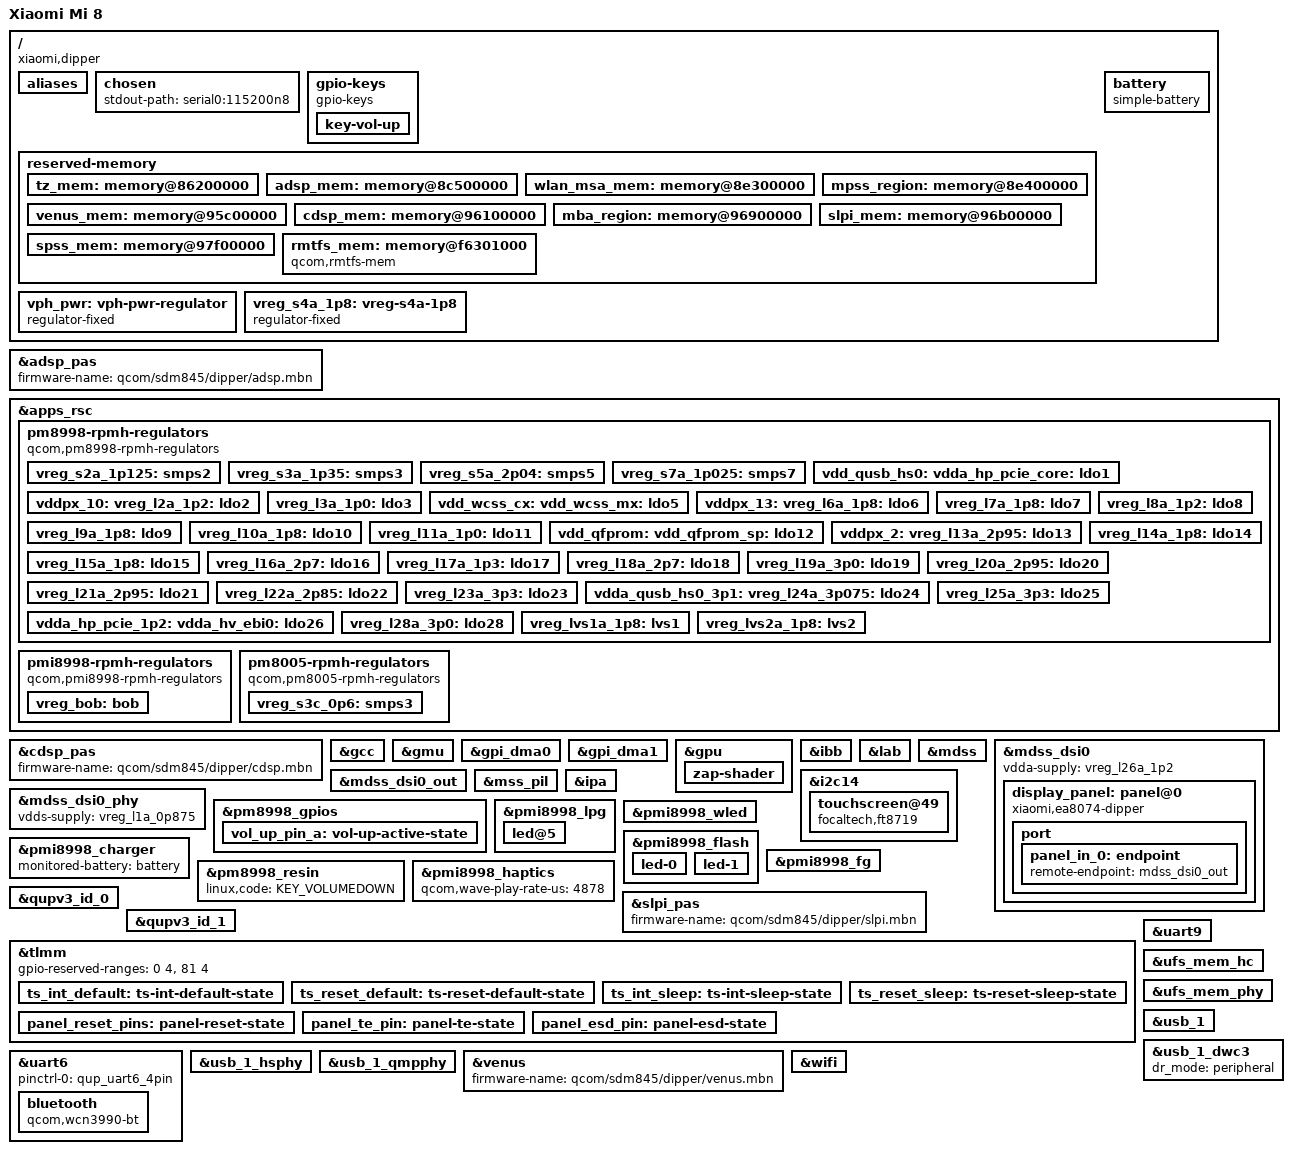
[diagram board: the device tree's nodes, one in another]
// SPDX-License-Identifier: GPL-2.0
/*
 * SDM845 Xiaomi Mi 8 (dipper) device tree source
 *
 * Copyright (c) 2024, Arseniy Velikanov <me@adomerle.xyz>
 */

/dts-v1/;

#include <dt-bindings/leds/common.h>
#include <dt-bindings/pinctrl/qcom,pmic-gpio.h>
#include <dt-bindings/regulator/qcom,rpmh-regulator.h>
#include "sdm845.dtsi"
#include "pm8998.dtsi"
#include "pmi8998.dtsi"

/*
 * Delete following upstream (sdm845.dtsi) reserved
 * memory mappings which are different in this device.
 */
/delete-node/ &tz_mem;
/delete-node/ &adsp_mem;
/delete-node/ &wlan_msa_mem;
/delete-node/ &mpss_region;
/delete-node/ &venus_mem;
/delete-node/ &cdsp_mem;
/delete-node/ &mba_region;
/delete-node/ &slpi_mem;
/delete-node/ &spss_mem;
/delete-node/ &rmtfs_mem;

/ {
	model = "Xiaomi Mi 8";
	compatible = "xiaomi,dipper", "qcom,sdm845";
	chassis-type = "handset";

	/* required for bootloader to select correct board */
	qcom,board-id = <79 0>;
	qcom,msm-id = <321 0x20001>;

	aliases {
		serial0 = &uart9;
		hsuart0 = &uart6;
	};

	chosen {
		stdout-path = "serial0:115200n8";
	};

	gpio-keys {
		compatible = "gpio-keys";
		autorepeat;

		pinctrl-names = "default";
		pinctrl-0 = <&vol_up_pin_a>;

		key-vol-up {
			label = "Volume Up";
			linux,code = <KEY_VOLUMEUP>;
			gpios = <&pm8998_gpios 6 GPIO_ACTIVE_LOW>;
		};
	};

	/* Reserved memory changes from downstream */
	reserved-memory {
		tz_mem: memory@86200000 {
			reg = <0 0x86200000 0 0x4900000>;
			no-map;
		};

		adsp_mem: memory@8c500000 {
			reg = <0 0x8c500000 0 0x1e00000>;
			no-map;
		};

		wlan_msa_mem: memory@8e300000 {
			reg = <0 0x8e300000 0 0x100000>;
			no-map;
		};

		mpss_region: memory@8e400000 {
			reg = <0 0x8e400000 0 0x7800000>;
			no-map;
		};

		venus_mem: memory@95c00000 {
			reg = <0 0x95c00000 0 0x500000>;
			no-map;
		};

		cdsp_mem: memory@96100000 {
			reg = <0 0x96100000 0 0x800000>;
			no-map;
		};

		mba_region: memory@96900000 {
			reg = <0 0x96900000 0 0x200000>;
			no-map;
		};

		slpi_mem: memory@96b00000 {
			reg = <0 0x96b00000 0 0x1400000>;
			no-map;
		};

		spss_mem: memory@97f00000 {
			reg = <0 0x97f00000 0 0x100000>;
			no-map;
		};

		rmtfs_mem: memory@f6301000 {
			compatible = "qcom,rmtfs-mem";
			reg = <0 0xf6301000 0 0x200000>;
			no-map;

			qcom,client-id = <1>;
			qcom,vmid = <15>;
		};
	};

	battery: battery {
		compatible = "simple-battery";

		charge-full-design-microamp-hours = <4000000>;
		voltage-min-design-microvolt = <3400000>;
		voltage-max-design-microvolt = <4400000>;
	};

	vph_pwr: vph-pwr-regulator {
		compatible = "regulator-fixed";
		regulator-name = "vph_pwr";
		regulator-min-microvolt = <3700000>;
		regulator-max-microvolt = <3700000>;
	};

	vreg_s4a_1p8: vreg-s4a-1p8 {
		compatible = "regulator-fixed";
		regulator-name = "vreg_s4a_1p8";

		regulator-min-microvolt = <1800000>;
		regulator-max-microvolt = <1800000>;

		regulator-always-on;
	};
};

&adsp_pas {
	status = "okay";
	firmware-name = "qcom/sdm845/dipper/adsp.mbn";
};

&apps_rsc {
	pm8998-rpmh-regulators {
		compatible = "qcom,pm8998-rpmh-regulators";
		qcom,pmic-id = "a";

		vdd-s1-supply = <&vph_pwr>;
		vdd-s2-supply = <&vph_pwr>;
		vdd-s3-supply = <&vph_pwr>;
		vdd-s4-supply = <&vph_pwr>;
		vdd-s5-supply = <&vph_pwr>;
		vdd-s6-supply = <&vph_pwr>;
		vdd-s7-supply = <&vph_pwr>;
		vdd-s8-supply = <&vph_pwr>;
		vdd-s9-supply = <&vph_pwr>;
		vdd-s10-supply = <&vph_pwr>;
		vdd-s11-supply = <&vph_pwr>;
		vdd-s12-supply = <&vph_pwr>;
		vdd-s13-supply = <&vph_pwr>;
		vdd-l1-l27-supply = <&vreg_s7a_1p025>;
		vdd-l2-l8-l17-supply = <&vreg_s3a_1p35>;
		vdd-l3-l11-supply = <&vreg_s7a_1p025>;
		vdd-l4-l5-supply = <&vreg_s7a_1p025>;
		vdd-l6-supply = <&vph_pwr>;
		vdd-l7-l12-l14-l15-supply = <&vreg_s5a_2p04>;
		vdd-l9-supply = <&vreg_bob>;
		vdd-l10-l23-l25-supply = <&vreg_bob>;
		vdd-l13-l19-l21-supply = <&vreg_bob>;
		vdd-l16-l28-supply = <&vreg_bob>;
		vdd-l18-l22-supply = <&vreg_bob>;
		vdd-l20-l24-supply = <&vreg_bob>;
		vdd-l26-supply = <&vreg_s3a_1p35>;
		vin-lvs-1-2-supply = <&vreg_s4a_1p8>;

		vreg_s2a_1p125: smps2 {
			regulator-min-microvolt = <1100000>;
			regulator-max-microvolt = <1100000>;
		};

		vreg_s3a_1p35: smps3 {
			regulator-min-microvolt = <1352000>;
			regulator-max-microvolt = <1352000>;
		};

		vreg_s5a_2p04: smps5 {
			regulator-min-microvolt = <1904000>;
			regulator-max-microvolt = <2040000>;
		};

		vreg_s7a_1p025: smps7 {
			regulator-min-microvolt = <900000>;
			regulator-max-microvolt = <1028000>;
		};

		vdd_qusb_hs0:
		vdda_hp_pcie_core:
		vdda_mipi_csi0_0p9:
		vdda_mipi_csi1_0p9:
		vdda_mipi_csi2_0p9:
		vdda_mipi_dsi0_pll:
		vdda_mipi_dsi1_pll:
		vdda_qlink_lv:
		vdda_qlink_lv_ck:
		vdda_qrefs_0p875:
		vdda_pcie_core:
		vdda_pll_cc_ebi01:
		vdda_pll_cc_ebi23:
		vdda_sp_sensor:
		vdda_ufs1_core:
		vdda_ufs2_core:
		vdda_usb1_ss_core:
		vdda_usb2_ss_core:
		vreg_l1a_0p875: ldo1 {
			regulator-min-microvolt = <880000>;
			regulator-max-microvolt = <880000>;
			regulator-initial-mode = <RPMH_REGULATOR_MODE_HPM>;
		};

		vddpx_10:
		vreg_l2a_1p2: ldo2 {
			regulator-min-microvolt = <1200000>;
			regulator-max-microvolt = <1200000>;
			regulator-initial-mode = <RPMH_REGULATOR_MODE_HPM>;
			regulator-always-on;
		};

		vreg_l3a_1p0: ldo3 {
			regulator-min-microvolt = <1000000>;
			regulator-max-microvolt = <1000000>;
			regulator-initial-mode = <RPMH_REGULATOR_MODE_HPM>;
		};

		vdd_wcss_cx:
		vdd_wcss_mx:
		vdda_wcss_pll:
		vreg_l5a_0p8: ldo5 {
			regulator-min-microvolt = <800000>;
			regulator-max-microvolt = <800000>;
			regulator-initial-mode = <RPMH_REGULATOR_MODE_HPM>;
		};

		vddpx_13:
		vreg_l6a_1p8: ldo6 {
			regulator-min-microvolt = <1856000>;
			regulator-max-microvolt = <1856000>;
			regulator-initial-mode = <RPMH_REGULATOR_MODE_HPM>;
		};

		vreg_l7a_1p8: ldo7 {
			regulator-min-microvolt = <1800000>;
			regulator-max-microvolt = <1800000>;
			regulator-initial-mode = <RPMH_REGULATOR_MODE_HPM>;
		};

		vreg_l8a_1p2: ldo8 {
			regulator-min-microvolt = <1200000>;
			regulator-max-microvolt = <1248000>;
			regulator-initial-mode = <RPMH_REGULATOR_MODE_HPM>;
		};

		vreg_l9a_1p8: ldo9 {
			regulator-min-microvolt = <1704000>;
			regulator-max-microvolt = <2928000>;
			regulator-initial-mode = <RPMH_REGULATOR_MODE_HPM>;
		};

		vreg_l10a_1p8: ldo10 {
			regulator-min-microvolt = <1704000>;
			regulator-max-microvolt = <2928000>;
			regulator-initial-mode = <RPMH_REGULATOR_MODE_HPM>;
		};

		vreg_l11a_1p0: ldo11 {
			regulator-min-microvolt = <1000000>;
			regulator-max-microvolt = <1048000>;
			regulator-initial-mode = <RPMH_REGULATOR_MODE_HPM>;
		};

		vdd_qfprom:
		vdd_qfprom_sp:
		vdda_apc1_cs_1p8:
		vdda_gfx_cs_1p8:
		vdda_qrefs_1p8:
		vdda_qusb_hs0_1p8:
		vddpx_11:
		vreg_l12a_1p8: ldo12 {
			regulator-min-microvolt = <1800000>;
			regulator-max-microvolt = <1800000>;
			regulator-initial-mode = <RPMH_REGULATOR_MODE_HPM>;
		};

		vddpx_2:
		vreg_l13a_2p95: ldo13 {
			regulator-min-microvolt = <1800000>;
			regulator-max-microvolt = <2960000>;
			regulator-initial-mode = <RPMH_REGULATOR_MODE_HPM>;
		};

		vreg_l14a_1p8: ldo14 {
			regulator-min-microvolt = <1800000>;
			regulator-max-microvolt = <1800000>;
			regulator-initial-mode = <RPMH_REGULATOR_MODE_HPM>;
		};

		vreg_l15a_1p8: ldo15 {
			regulator-min-microvolt = <1800000>;
			regulator-max-microvolt = <1800000>;
			regulator-initial-mode = <RPMH_REGULATOR_MODE_HPM>;
		};

		vreg_l16a_2p7: ldo16 {
			regulator-min-microvolt = <2704000>;
			regulator-max-microvolt = <2704000>;
			regulator-initial-mode = <RPMH_REGULATOR_MODE_HPM>;
		};

		vreg_l17a_1p3: ldo17 {
			regulator-min-microvolt = <1304000>;
			regulator-max-microvolt = <1304000>;
			regulator-initial-mode = <RPMH_REGULATOR_MODE_HPM>;
		};

		vreg_l18a_2p7: ldo18 {
			regulator-min-microvolt = <2704000>;
			regulator-max-microvolt = <2960000>;
			regulator-initial-mode = <RPMH_REGULATOR_MODE_HPM>;
		};

		vreg_l19a_3p0: ldo19 {
			regulator-min-microvolt = <2856000>;
			regulator-max-microvolt = <3104000>;
			regulator-initial-mode = <RPMH_REGULATOR_MODE_HPM>;
		};

		vreg_l20a_2p95: ldo20 {
			regulator-min-microvolt = <2704000>;
			regulator-max-microvolt = <2960000>;
			regulator-initial-mode = <RPMH_REGULATOR_MODE_HPM>;
		};

		vreg_l21a_2p95: ldo21 {
			regulator-min-microvolt = <2704000>;
			regulator-max-microvolt = <2960000>;
			regulator-initial-mode = <RPMH_REGULATOR_MODE_HPM>;
		};

		vreg_l22a_2p85: ldo22 {
			regulator-min-microvolt = <2864000>;
			regulator-max-microvolt = <3312000>;
			regulator-initial-mode = <RPMH_REGULATOR_MODE_HPM>;
		};

		vreg_l23a_3p3: ldo23 {
			regulator-min-microvolt = <3000000>;
			regulator-max-microvolt = <3312000>;
			regulator-initial-mode = <RPMH_REGULATOR_MODE_HPM>;
		};

		vdda_qusb_hs0_3p1:
		vreg_l24a_3p075: ldo24 {
			regulator-min-microvolt = <3088000>;
			regulator-max-microvolt = <3088000>;
			regulator-initial-mode = <RPMH_REGULATOR_MODE_HPM>;
		};

		vreg_l25a_3p3: ldo25 {
			regulator-min-microvolt = <3300000>;
			regulator-max-microvolt = <3312000>;
			regulator-initial-mode = <RPMH_REGULATOR_MODE_HPM>;
		};

		vdda_hp_pcie_1p2:
		vdda_hv_ebi0:
		vdda_hv_ebi1:
		vdda_hv_ebi2:
		vdda_hv_ebi3:
		vdda_mipi_csi_1p25:
		vdda_mipi_dsi0_1p2:
		vdda_mipi_dsi1_1p2:
		vdda_pcie_1p2:
		vdda_ufs1_1p2:
		vdda_ufs2_1p2:
		vdda_usb1_ss_1p2:
		vdda_usb2_ss_1p2:
		vreg_l26a_1p2: ldo26 {
			regulator-min-microvolt = <1200000>;
			regulator-max-microvolt = <1200000>;
			regulator-initial-mode = <RPMH_REGULATOR_MODE_HPM>;
		};

		vreg_l28a_3p0: ldo28 {
			regulator-min-microvolt = <2856000>;
			regulator-max-microvolt = <3008000>;
			regulator-initial-mode = <RPMH_REGULATOR_MODE_HPM>;
		};

		vreg_lvs1a_1p8: lvs1 {
			regulator-min-microvolt = <1800000>;
			regulator-max-microvolt = <1800000>;
		};

		vreg_lvs2a_1p8: lvs2 {
			regulator-min-microvolt = <1800000>;
			regulator-max-microvolt = <1800000>;
		};
	};

	pmi8998-rpmh-regulators {
		compatible = "qcom,pmi8998-rpmh-regulators";
		qcom,pmic-id = "b";

		vdd-bob-supply = <&vph_pwr>;

		vreg_bob: bob {
			regulator-min-microvolt = <3312000>;
			regulator-max-microvolt = <3600000>;
			regulator-initial-mode = <RPMH_REGULATOR_MODE_AUTO>;
			regulator-allow-bypass;
		};
	};

	pm8005-rpmh-regulators {
		compatible = "qcom,pm8005-rpmh-regulators";
		qcom,pmic-id = "c";

		vdd-s1-supply = <&vph_pwr>;
		vdd-s2-supply = <&vph_pwr>;
		vdd-s3-supply = <&vph_pwr>;
		vdd-s4-supply = <&vph_pwr>;

		vreg_s3c_0p6: smps3 {
			regulator-min-microvolt = <600000>;
			regulator-max-microvolt = <600000>;
		};
	};
};

&cdsp_pas {
	status = "okay";
	firmware-name = "qcom/sdm845/dipper/cdsp.mbn";
};

&gcc {
	protected-clocks = <GCC_QSPI_CORE_CLK>,
			   <GCC_QSPI_CORE_CLK_SRC>,
			   <GCC_QSPI_CNOC_PERIPH_AHB_CLK>,
			   <GCC_LPASS_Q6_AXI_CLK>,
			   <GCC_LPASS_SWAY_CLK>;
};

&gmu {
	status = "okay";
};

&gpi_dma0 {
	status = "okay";
};

&gpi_dma1 {
	status = "okay";
};

&gpu {
	status = "okay";

	zap-shader {
		memory-region = <&gpu_mem>;
		firmware-name = "qcom/sdm845/dipper/a630_zap.mbn";
	};
};

&ibb {
	regulator-min-microvolt = <4600000>;
	regulator-max-microvolt = <6000000>;
	regulator-over-current-protection;
	regulator-pull-down;
	regulator-soft-start;
	qcom,discharge-resistor-kohms = <300>;
};

&lab {
	regulator-min-microvolt = <4600000>;
	regulator-max-microvolt = <6000000>;
	regulator-pull-down;
	regulator-soft-start;
};

&mdss {
	status = "okay";
};

&mdss_dsi0 {
	status = "okay";
	vdda-supply = <&vreg_l26a_1p2>;

	display_panel: panel@0 {
	    compatible = "xiaomi,ea8074-dipper", "samsung,ea8074";
		reg = <0>;
		vddio-supply = <&vreg_l14a_1p8>;
		vddpos-supply = <&lab>;
		vddneg-supply = <&ibb>;

		backlight = <&pmi8998_wled>;
		reset-gpios = <&tlmm 6 GPIO_ACTIVE_LOW>;

		pinctrl-names = "default";
		pinctrl-0 = <&panel_reset_pins &panel_te_pin &panel_esd_pin>;

		status = "okay";

		port {
			panel_in_0: endpoint {
				remote-endpoint = <&mdss_dsi0_out>;
			};
		};
	};
};

&mdss_dsi0_out {
	remote-endpoint = <&panel_in_0>;
	data-lanes = <0 1 2 3>;
};

&mdss_dsi0_phy {
	status = "okay";
	vdds-supply = <&vreg_l1a_0p875>;
};

&mss_pil {
	status = "okay";
	firmware-name = "qcom/sdm845/dipper/mba.mbn", "qcom/sdm845/dipper/modem.mbn";
};

&ipa {
	qcom,gsi-loader = "self";
	memory-region = <&ipa_fw_mem>;
	firmware-name = "qcom/sdm845/dipper/ipa_fws.mbn";
	status = "okay";
};

&i2c14 {
	status = "okay";

	touchscreen@49 {
		compatible = "focaltech,ft8719";
		reg = <0x49>;

		interrupts-extended = <&tlmm 31 IRQ_TYPE_EDGE_FALLING>;
		reset-gpios = <&tlmm 32 GPIO_ACTIVE_LOW>;

		iovcc-supply = <&vreg_l14a_1p8>;

		pinctrl-0 = <&ts_int_default &ts_reset_default>;
		pinctrl-1 = <&ts_int_sleep &ts_reset_sleep>;
		pinctrl-names = "default", "sleep";

		touchscreen-size-x = <1080>;
		touchscreen-size-y = <2248>;
	};
};

&pm8998_gpios {
	vol_up_pin_a: vol-up-active-state {
		pins = "gpio6";
		function = "normal";
		input-enable;
		bias-pull-up;
		qcom,drive-strength = <PMIC_GPIO_STRENGTH_NO>;
	};
};

&pmi8998_lpg {
	status = "okay";

	led@5 {
		reg = <5>;
		color = <LED_COLOR_ID_WHITE>;
		function = LED_FUNCTION_STATUS;
	};
};

&pmi8998_wled {
	status = "okay";
	qcom,current-boost-limit = <970>;
	qcom,ovp-millivolt = <29600>;
	qcom,current-limit-microamp = <20000>;
	qcom,num-strings = <2>;
	qcom,switching-freq = <600>;
	qcom,external-pfet;
	qcom,cabc;
};

&pmi8998_charger {
	monitored-battery = <&battery>;

	status = "okay";
};

&pmi8998_flash {
	status = "okay";

	led-0 {
		function = LED_FUNCTION_FLASH;
		color = <LED_COLOR_ID_WHITE>;
		led-sources = <1>;
		led-max-microamp = <500000>;
		flash-max-microamp = <1500000>;
		flash-max-timeout-us = <1280000>;
	};

	led-1 {
		function = LED_FUNCTION_FLASH;
		color = <LED_COLOR_ID_YELLOW>;
		led-sources = <2>;
		led-max-microamp = <500000>;
		flash-max-microamp = <1500000>;
		flash-max-timeout-us = <1280000>;
	};
};

&pmi8998_fg {
	status = "okay";

	power-supplies = <&pmi8998_charger>;
	monitored-battery = <&battery>;
};

&pm8998_resin {
	linux,code = <KEY_VOLUMEDOWN>;
	status = "okay";
};

&pmi8998_haptics {
	status = "okay";
	qcom,wave-play-rate-us = <4878>;
};

&slpi_pas {
	firmware-name = "qcom/sdm845/dipper/slpi.mbn";
	status = "okay";
};

&qupv3_id_0 {
	status = "okay";
};

&qupv3_id_1 {
	status = "okay";
};

&tlmm {
	gpio-reserved-ranges = <0 4>, <81 4>;

	ts_int_default: ts-int-default-state {
		pins = "gpio31";
		function = "gpio";
		drive-strength = <16>;
		bias-pull-down;
		input-enable;
	};

	ts_reset_default: ts-reset-default-state {
		pins = "gpio32";
		function = "gpio";
		drive-strength = <16>;
		output-high;
	};

	ts_int_sleep: ts-int-sleep-state {
		pins = "gpio31";
		function = "gpio";
		drive-strength = <2>;
		bias-pull-down;
		input-enable;
	};

	ts_reset_sleep: ts-reset-sleep-state {
		pins = "gpio32";
		function = "gpio";
		drive-strength = <2>;
		bias-disable;
		output-low;
	};

	panel_reset_pins: panel-reset-state {
		pins = "gpio6", "gpio25", "gpio26";
		function = "gpio";
		drive-strength = <8>;
		bias-disable;
	};

	panel_te_pin: panel-te-state {
		pins = "gpio10";
		function = "mdp_vsync";
		drive-strength = <2>;
		bias-disable;
	};

	panel_esd_pin: panel-esd-state {
		pins = "gpio52";
		function = "gpio";
		drive-strength = <2>;
		bias-pull-down;
	};
};

&uart6 {
	status = "okay";

	pinctrl-0 = <&qup_uart6_4pin>;

	bluetooth {
		compatible = "qcom,wcn3990-bt";

		vddio-supply = <&vreg_s4a_1p8>;
		vddxo-supply = <&vreg_l7a_1p8>;
		vddrf-supply = <&vreg_l17a_1p3>;
		vddch0-supply = <&vreg_l25a_3p3>;
		max-speed = <3200000>;
	};
};

&uart9 {
	status = "okay";
};

&ufs_mem_hc {
	status = "okay";

	reset-gpios = <&tlmm 150 GPIO_ACTIVE_LOW>;

	vcc-supply = <&vreg_l20a_2p95>;
	vcc-max-microamp = <800000>;
};

&ufs_mem_phy {
	status = "okay";

	vdda-phy-supply = <&vreg_l1a_0p875>;
	vdda-pll-supply = <&vreg_l26a_1p2>;
};

&usb_1 {
	status = "okay";
};

&usb_1_dwc3 {
	dr_mode = "peripheral";
};

&usb_1_hsphy {
	status = "okay";

	vdd-supply = <&vreg_l1a_0p875>;
	vdda-pll-supply = <&vreg_l12a_1p8>;
	vdda-phy-dpdm-supply = <&vreg_l24a_3p075>;

	qcom,imp-res-offset-value = <8>;
	qcom,hstx-trim-value = <QUSB2_V2_HSTX_TRIM_21_6_MA>;
	qcom,preemphasis-level = <QUSB2_V2_PREEMPHASIS_5_PERCENT>;
	qcom,preemphasis-width = <QUSB2_V2_PREEMPHASIS_WIDTH_HALF_BIT>;
};

&usb_1_qmpphy {
	status = "okay";

	vdda-phy-supply = <&vreg_l26a_1p2>;
	vdda-pll-supply = <&vreg_l1a_0p875>;
};

&venus {
	status = "okay";
	firmware-name = "qcom/sdm845/dipper/venus.mbn";
};

&wifi {
	status = "okay";

	vdd-0.8-cx-mx-supply = <&vreg_l5a_0p8>;
	vdd-1.8-xo-supply = <&vreg_l7a_1p8>;
	vdd-1.3-rfa-supply = <&vreg_l17a_1p3>;
	vdd-3.3-ch0-supply = <&vreg_l25a_3p3>;
	vdd-3.3-ch1-supply = <&vreg_l23a_3p3>;

	qcom,snoc-host-cap-skip-quirk;
	qcom,ath10k-calibration-variant = "xiaomi_dipper";
};
